AUTOSAR XML (schema 4-0-3)
standard types defined: UInt32, UInt8
package /AUTOSAR_Platform/DataConstrs
  range DC_UInt8: raw 0..255
package /PATAC/MSM/ComponentTypes
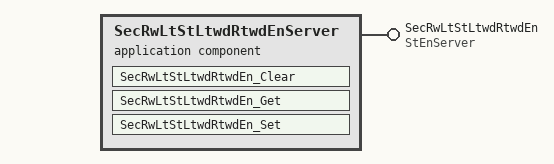
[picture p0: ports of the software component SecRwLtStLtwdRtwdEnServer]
  application sw component type SecRwLtStLtwdRtwdEnServer
    provide port SecRwLtStLtwdRtwdEn: provided-com-specs=[{operation=Clear, queue-length=1}, {operation=Get, queue-length=1}, {operation=Set, queue-length=1}], provided-interface=StEnServer
    behavior SecRwLtStLtwdRtwdEnServer_InternalBehavior
      operation invoked event OIT_SecRwLtStLtwdRtwdEn_Clear_SecRwLtStLtwdRtwdEn_Clear: start-on-event=SecRwLtStLtwdRtwdEn_Clear, operation=SecRwLtStLtwdRtwdEn.Clear
      operation invoked event OIT_SecRwLtStLtwdRtwdEn_Get_SecRwLtStLtwdRtwdEn_Get: start-on-event=SecRwLtStLtwdRtwdEn_Get, operation=SecRwLtStLtwdRtwdEn.Get
      operation invoked event OIT_SecRwLtStLtwdRtwdEn_Set_SecRwLtStLtwdRtwdEn_Set: start-on-event=SecRwLtStLtwdRtwdEn_Set, operation=SecRwLtStLtwdRtwdEn.Set
      runnable SecRwLtStLtwdRtwdEn_Clear
      runnable SecRwLtStLtwdRtwdEn_Get
      runnable SecRwLtStLtwdRtwdEn_Set
  swc implementation SecRwLtStLtwdRtwdEnServer_Implementation: behavior=SecRwLtStLtwdRtwdEnServer_InternalBehavior
    code-descriptors:
      code Default: artifact-descriptors=autosar-engineering-object={short-label=Default, category=SWSRC}
package /PATAC/MSM/ModeAdjust/PortInterface
  client server interface StEnServer
    operation Clear
      arg data: type=UInt8, direction=IN, server-argument-impl-policy=USE-ARGUMENT-TYPE
    operation Get
      arg data: type=UInt32, direction=OUT, server-argument-impl-policy=USE-ARGUMENT-TYPE
    operation Set
      arg data: type=UInt8, direction=IN, server-argument-impl-policy=USE-ARGUMENT-TYPE
